VERSION ""

NS_ :

BS_:

BU_: XXX

BO_ 80 SEATBELT: 8 XXX
 SG_ DRIVER_SEATBELT : 14|1@0+ (1,0) [0|1] "" XXX

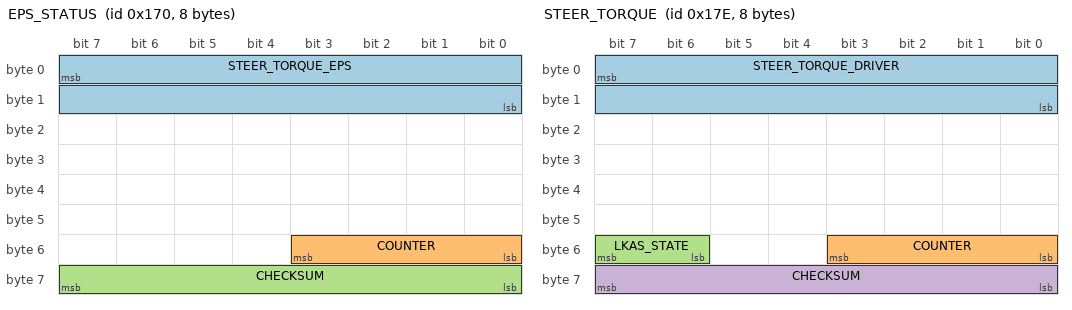
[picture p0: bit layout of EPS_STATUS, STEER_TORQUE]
BO_ 368 EPS_STATUS: 8 XXX
 SG_ STEER_TORQUE_EPS : 7|16@0- (1,0) [0|0] "" XXX
 SG_ COUNTER : 51|4@0+ (1,0) [0|15] "" XXX
 SG_ CHECKSUM : 63|8@0+ (1,0) [0|255] "" XXX

BO_ 382 STEER_TORQUE: 8 XXX
 SG_ STEER_TORQUE_DRIVER : 7|16@0- (0.01,0) [0|0] "" XXX
 SG_ COUNTER : 51|4@0+ (1,0) [0|15] "" XXX
 SG_ LKAS_STATE : 55|2@0+ (1,0) [0|3] "" XXX
 SG_ CHECKSUM : 63|8@0+ (1,0) [0|255] "" XXX

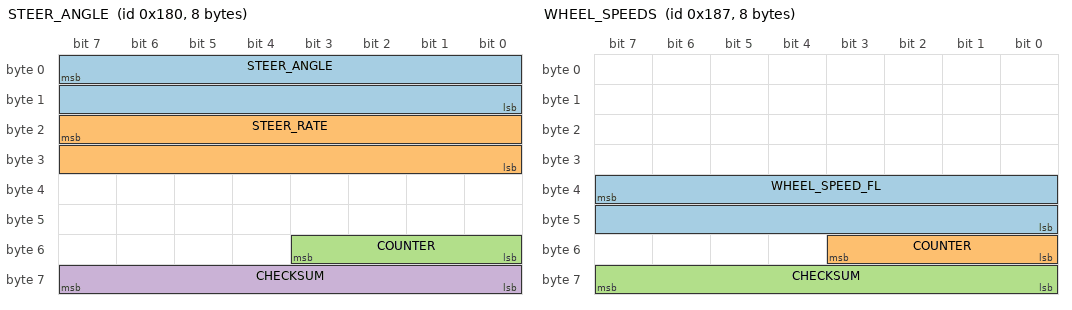
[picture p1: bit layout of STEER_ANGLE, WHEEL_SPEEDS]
BO_ 384 STEER_ANGLE: 8 XXX
 SG_ STEER_ANGLE : 7|16@0- (0.1,0) [-476|476] "deg" XXX
 SG_ STEER_RATE : 23|16@0- (1,0) [0|0] "deg/s" XXX
 SG_ COUNTER : 51|4@0+ (1,0) [0|15] "" XXX
 SG_ CHECKSUM : 63|8@0+ (1,0) [0|255] "" XXX

BO_ 391 WHEEL_SPEEDS: 8 XXX
 SG_ WHEEL_SPEED_FL : 39|16@0+ (0.05,0) [0|65535] "km/h" XXX
 SG_ COUNTER : 51|4@0+ (1,0) [0|15] "" XXX
 SG_ CHECKSUM : 63|8@0+ (1,0) [0|255] "" XXX

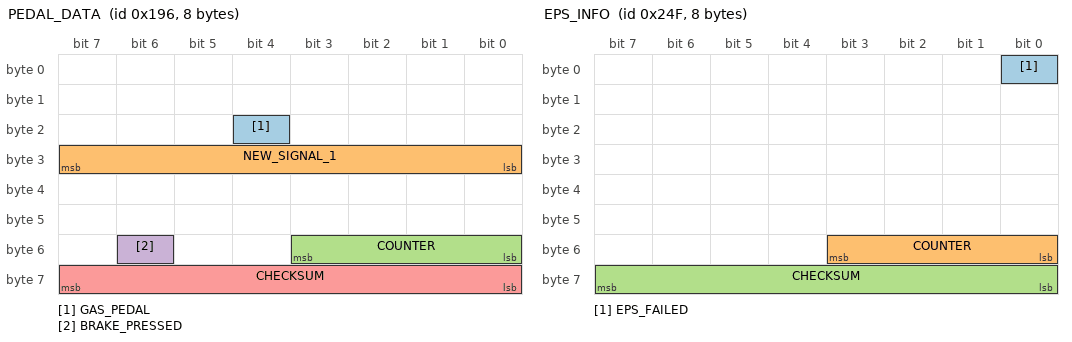
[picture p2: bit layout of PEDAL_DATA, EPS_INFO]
BO_ 406 PEDAL_DATA: 8 XXX
 SG_ GAS_PEDAL : 20|1@0+ (1,0) [0|1] "" XXX
 SG_ NEW_SIGNAL_1 : 31|8@0+ (1,0) [0|255] "" XXX
 SG_ COUNTER : 51|4@0+ (1,0) [0|15] "" XXX
 SG_ BRAKE_PRESSED : 54|1@0+ (1,0) [0|1] "" XXX
 SG_ CHECKSUM : 63|8@0+ (1,0) [0|255] "" XXX

BO_ 442 STEER_COMMAND: 32 XXX
 SG_ STEER_ANGLE : 7|16@0- (0.1,0) [-500|500] "deg" XXX
 SG_ STEER_REQUEST : 23|1@0+ (1,0) [0|1] "" XXX
 SG_ STEER_MAX_ANGLE : 39|8@0+ (0.1,0) [0|25.5] "" XXX
 SG_ STEER_MIN_ANGLE : 47|8@0+ (0.1,0) [-25.5|0] "" XXX
 SG_ COUNTER : 51|4@0+ (1,0) [0|15] "" XXX
 SG_ CHECKSUM : 63|8@0+ (1,0) [0|255] "" XXX
 SG_ COUNTER_1 : 115|4@0+ (1,0) [0|15] "" XXX
 SG_ CHECKSUM_1 : 127|8@0+ (1,0) [0|255] "" XXX
 SG_ COUNTER_2 : 179|4@0+ (1,0) [0|15] "" XXX
 SG_ CHECKSUM_2 : 191|8@0+ (1,0) [0|255] "" XXX
 SG_ COUNTER_3 : 243|4@0+ (1,0) [0|15] "" XXX
 SG_ CHECKSUM_3 : 255|8@0+ (1,0) [0|255] "" XXX

BO_ 580 ACC_COMMAND: 32 XXX
 SG_ ACCEL_CMD : 7|16@0- (0.001,0) [-10|10] "m/s2" XXX
 SG_ ACC_AEBCtrlType : 34|3@0+ (1,0) [0|7] "" XXX
 SG_ FCW_PRE_WARNING : 35|1@0+ (1,0) [0|1] "" XXX
 SG_ COUNTER : 51|4@0+ (1,0) [0|15] "" XXX
 SG_ ACC_MODE : 53|1@0+ (1,0) [0|1] "" XXX
 SG_ ACCEL_ACTIVE : 54|1@0+ (1,0) [0|1] "" XXX
 SG_ ACCEL_REQUEST : 55|1@0+ (1,0) [0|1] "" XXX
 SG_ CHECKSUM : 63|8@0+ (1,0) [0|255] "" XXX
 SG_ COUNTER_1 : 115|4@0+ (1,0) [0|15] "" XXX
 SG_ CHECKSUM_1 : 127|8@0+ (1,0) [0|255] "" XXX
 SG_ COUNTER_2 : 179|4@0+ (1,0) [0|15] "" XXX
 SG_ CHECKSUM_2 : 191|8@0+ (1,0) [0|255] "" XXX
 SG_ COUNTER_3 : 243|4@0+ (1,0) [0|15] "" XXX
 SG_ CHECKSUM_3 : 255|8@0+ (1,0) [0|255] "" XXX

BO_ 591 EPS_INFO: 8 XXX
 SG_ EPS_FAILED : 0|1@0+ (1,0) [0|1] "" XXX
 SG_ COUNTER : 51|4@0+ (1,0) [0|15] "" XXX
 SG_ CHECKSUM : 63|8@0+ (1,0) [0|255] "" XXX

BO_ 631 BRAKE_MAYBE: 8 XXX
 SG_ BRAKE_MAYBE : 7|1@0+ (1,0) [0|1] "" XXX

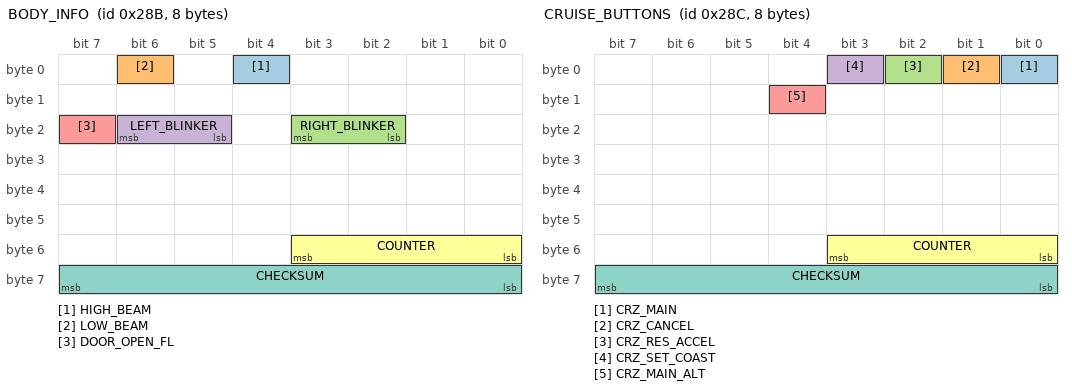
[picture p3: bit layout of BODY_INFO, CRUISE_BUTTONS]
BO_ 651 BODY_INFO: 8 XXX
 SG_ HIGH_BEAM : 4|1@0+ (1,0) [0|1] "" XXX
 SG_ LOW_BEAM : 6|1@0+ (1,0) [0|1] "" XXX
 SG_ RIGHT_BLINKER : 19|2@0+ (1,0) [0|3] "" XXX
 SG_ LEFT_BLINKER : 22|2@0+ (1,0) [0|3] "" XXX
 SG_ DOOR_OPEN_FL : 23|1@0+ (1,0) [0|1] "" XXX
 SG_ COUNTER : 51|4@0+ (1,0) [0|15] "" XXX
 SG_ CHECKSUM : 63|8@0+ (1,0) [0|255] "" XXX

BO_ 652 CRUISE_BUTTONS: 8 XXX
 SG_ CRZ_MAIN : 0|1@0+ (1,0) [0|1] "" XXX
 SG_ CRZ_CANCEL : 1|1@0+ (1,0) [0|1] "" XXX
 SG_ CRZ_RES_ACCEL : 2|1@0+ (1,0) [0|1] "" XXX
 SG_ CRZ_SET_COAST : 3|1@0+ (1,0) [0|1] "" XXX
 SG_ CRZ_MAIN_ALT : 12|1@0+ (1,0) [0|1] "" XXX
 SG_ COUNTER : 51|4@0+ (1,0) [0|15] "" XXX
 SG_ CHECKSUM : 63|8@0+ (1,0) [0|255] "" XXX

BO_ 775 ACC_HUD: 64 XXX
 SG_ SET_SPEED : 26|3@0+ (1,0) [0|7] "" XXX
 SG_ DISTANCE_LEVEL : 47|2@0+ (1,0) [0|3] "" XXX
 SG_ COUNTER : 51|4@0+ (1,0) [0|15] "" XXX
 SG_ CHECKSUM : 63|8@0+ (1,0) [0|255] "" XXX
 SG_ COUNTER_1 : 115|4@0+ (1,0) [0|15] "" XXX
 SG_ CHECKSUM_1 : 127|8@0+ (1,0) [0|255] "" XXX
 SG_ COUNTER_2 : 179|4@0+ (1,0) [0|15] "" XXX
 SG_ CHECKSUM_2 : 191|8@0+ (1,0) [0|255] "" XXX
 SG_ COUNTER_3 : 243|4@0+ (1,0) [0|15] "" XXX
 SG_ CHECKSUM_3 : 255|8@0+ (1,0) [0|255] "" XXX
 SG_ COUNTER_4 : 307|4@0+ (1,0) [0|15] "" XXX
 SG_ CHECKSUM_4 : 319|8@0+ (1,0) [0|255] "" XXX
 SG_ COUNTER_5 : 371|4@0+ (1,0) [0|15] "" XXX
 SG_ CHECKSUM_5 : 383|8@0+ (1,0) [0|255] "" XXX
 SG_ COUNTER_6 : 435|4@0+ (1,0) [0|15] "" XXX
 SG_ CHECKSUM_6 : 447|8@0+ (1,0) [0|255] "" XXX
 SG_ COUNTER_7 : 499|4@0+ (1,0) [0|15] "" XXX
 SG_ CHECKSUM_7 : 511|8@0+ (1,0) [0|255] "" XXX

BO_ 794 ADAS_INFO: 32 XXX
 SG_ STEER_PRESSED : 6|1@0+ (1,0) [0|1] "" XXX
 SG_ ACC_IACC_HWA_ENABLE : 7|1@0+ (1,0) [0|1] "" XXX
 SG_ ACC_IACC_HWA_MODE : 15|2@0+ (1,0) [0|3] "" XXX
 SG_ COUNTER : 51|4@0+ (1,0) [0|15] "" XXX
 SG_ CHECKSUM : 63|8@0+ (1,0) [0|255] "" XXX
 SG_ COUNTER_1 : 115|4@0+ (1,0) [0|15] "" XXX
 SG_ CHECKSUM_1 : 127|8@0+ (1,0) [0|255] "" XXX
 SG_ COUNTER_2 : 179|4@0+ (1,0) [0|15] "" XXX
 SG_ CHECKSUM_2 : 191|8@0+ (1,0) [0|255] "" XXX
 SG_ COUNTER_3 : 243|4@0+ (1,0) [0|15] "" XXX
 SG_ CHECKSUM_3 : 255|8@0+ (1,0) [0|255] "" XXX

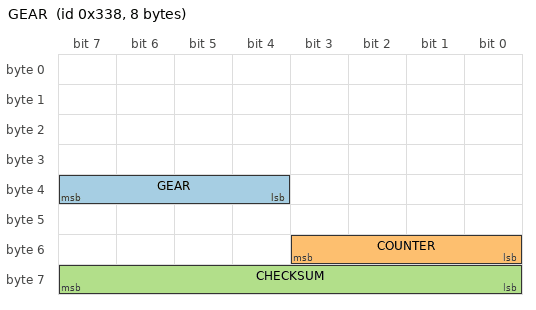
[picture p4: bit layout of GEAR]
BO_ 824 GEAR: 8 XXX
 SG_ GEAR : 39|4@0+ (1,-7) [0|15] "" XXX
 SG_ COUNTER : 51|4@0+ (1,0) [0|15] "" XXX
 SG_ CHECKSUM : 63|8@0+ (1,0) [0|255] "" XXX

CM_ SG_ 384 STEER_ANGLE "1";
VAL_ 824 GEAR 2 "N" 1 "R" 3 "D" 0 "P";
